# WUGEN_MPU register map
Vendor: Texas Instruments
Peripheral module from a debugger description file (folder omap5430_ES2_PUBLIC).
Registers are 32-bit, read-write, reset 0xFFFFFFFF unless marked. A register's access mark holds for its fields unless they carry their own. Offsets are as the file gives them; lines under a group give offsets from that group; [hi:lo] are bit positions; {n}, {i} and the like mark numbered series; 'fields as' and 'values as' point back to an identical list; <NAME> marks a mode.

## WUGEN_MPU
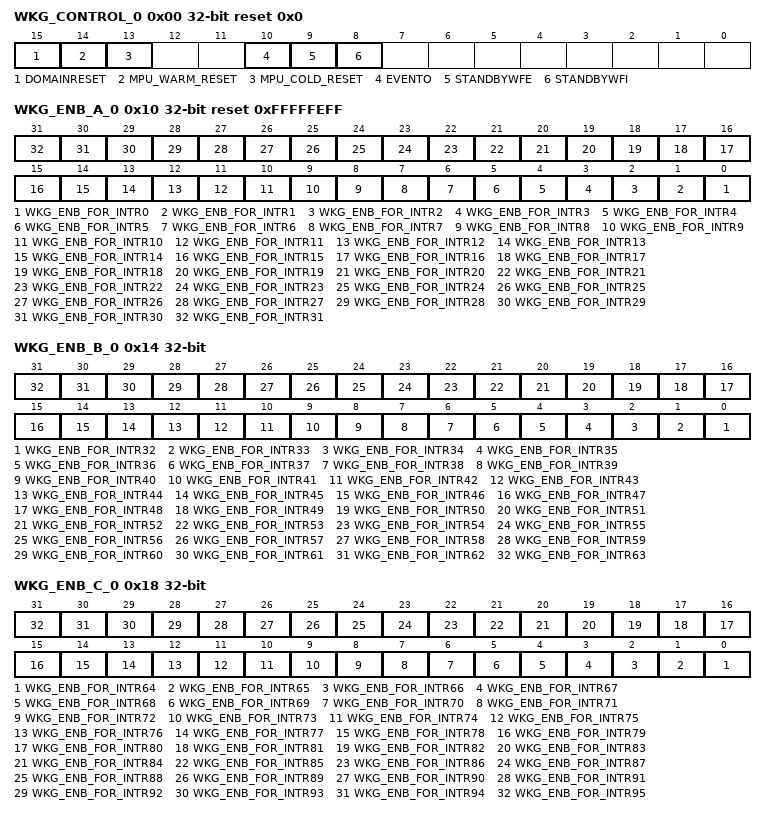
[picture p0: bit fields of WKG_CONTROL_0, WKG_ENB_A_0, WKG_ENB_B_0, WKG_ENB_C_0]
0x00 WKG_CONTROL_0 access not given reset 0x0 — Wake-up generator status register for MPU_C0
  [15] DOMAINRESET ro — MPU always-on power domain (PD_MPUAON) reset status bit. It shows if the reset occurred previously. 0x0: no reset occur 0x1: reset occur
  [14] MPU_WARM_RESET — This bit is set when the MPU_WARM_RESET signal is asserted. 0x0: MPU_WARM_RESET reset signal has not been asserted 0x1: MPU_WARM_RESET reset request has been asserted (access RW (WCtoClr))
  [13] MPU_COLD_RESET — This bit is set when the MPU_COLD_RESET signal is asserted. 0x0: MPU_COLD_RESET reset signal has not been asserted 0x1: MPU_COLD_RESET reset request has been asserted (access RW (WCtoClr))
  [10] EVENTO — EVENTO status bit. The event output signal is active, when one SEV instruction is executed. This bit is set when a rising edge of EVENTO from CPU is detected. 0x0: Rising edge of EVENTO is not detected 0x1: Rising edge of EVENTO is detected (access RW (WCtoClr))
  [9] STANDBYWFE — This bit gives software the visibility to track whether WFE mode have been entered. 0x0: WFE mode has not been entered 0x1: WFE mode has been entered (access RW (WCtoClr))
  [8] STANDBYWFI — This bit gives software the visibility to track whether WFI mode have been entered. 0x0: WFI mode has not been entered 0x1: WFI mode has been entered (access RW (WCtoClr))
0x10 WKG_ENB_A_0 reset 0xFFFFFEFF — This register enables the interrupts (for MPU_C0) from MPU_IRQ_0 to MPU_IRQ_31. Write 0x0:Disable interrupt. Write 0x1: Enable interrupt.
  [n] WKG_ENB_FOR_INTR{n} (n=0..31)
0x14 WKG_ENB_B_0 — This register enables the interrupts (for MPU_C0) from MPU_IRQ_32 to MPU_IRQ_63. Write 0x0: Disable interrupt. Write 0x1: Enable interrupt.
  [n-32] WKG_ENB_FOR_INTR{n} (n=32..63)
0x18 WKG_ENB_C_0 — This register enables the interrupts (for MPU_C0) from MPU_IRQ_64 to MPU_IRQ_95. Write 0x0: Disable interrupt. Write 0x1: Enable interrupt.
  [n-64] WKG_ENB_FOR_INTR{n} (n=64..95)
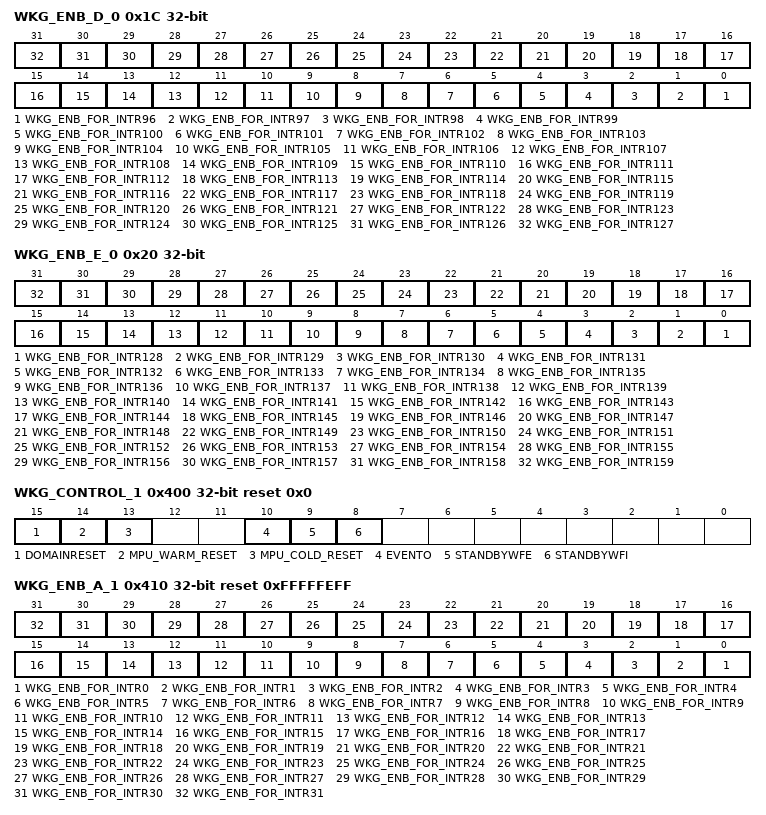
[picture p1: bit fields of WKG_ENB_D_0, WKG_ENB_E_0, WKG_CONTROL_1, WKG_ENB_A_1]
0x1C WKG_ENB_D_0 — This register enables the interrupts (for MPU_C0) from MPU_IRQ_96 to MPU_IRQ_127. Write 0x0: Disable interrupt. Write 0x1: Enable interrupt.
  [n-96] WKG_ENB_FOR_INTR{n} (n=96..127)
0x20 WKG_ENB_E_0 — This register enables the interrupts (for MPU_C0) from MPU_IRQ_128 to MPU_IRQ_159. Write 0x0: Disable interrupt. Write 0x1: Enable interrupt.
  [n-128] WKG_ENB_FOR_INTR{n} (n=128..159)
0x400 WKG_CONTROL_1 access not given reset 0x0 — Wake-up generator status register for MPU_C1
  [15] DOMAINRESET — MPU always-on power domain (PD_MPUAON) reset status bit. It shows if the reset occurred previously. 0x0: No reset occurred. 0x1: Reset occurred. (access RW (WCtoClr))
  [14] MPU_WARM_RESET — This bit is set when the MPU_WARM_RESET signal is asserted. 0x0: MPU_WARM_RESET reset signal has not been asserted. 0x1: MPU_WARM_RESET reset request has been asserted. (access RW (WCtoClr))
  [13] MPU_COLD_RESET — This bit is set when the MPU_COLD_RESET signal is asserted. 0x0: MPU_COLD_RESET reset signal has not been asserted. 0x1: MPU_COLD_RESET reset request has been asserted. (access RW (WCtoClr))
  [10] EVENTO — EVENTO status bit. The event output signal is active, when one SEV instruction is executed. This bit is set when a rising edge of EVENTO from CPU is detected. 0x0: Rising edge of EVENTO is not detected. 0x1: Rising edge of EVENTO is detected. (access RW (WCtoClr))
  [9] STANDBYWFE — This bit gives software the visibility to track whether WFE mode have been entered. 0x0: WFE mode has not been entered. 0x1: WFE mode has been entered. (access RW (WCtoClr))
  [8] STANDBYWFI — This bit gives software the visibility to track whether WFI mode have been entered. 0x0: WFI mode has not been entered. 0x1: WFI mode has been entered. (access RW (WCtoClr))
0x410 WKG_ENB_A_1 reset 0xFFFFFEFF — This register enables the interrupts (for MPU_C1) from MPU_IRQ_0 to MPU_IRQ_31. Write 0x0: Disable interrupt. Write 0x1: Enable interrupt.
  [n] WKG_ENB_FOR_INTR{n} (n=0..31)
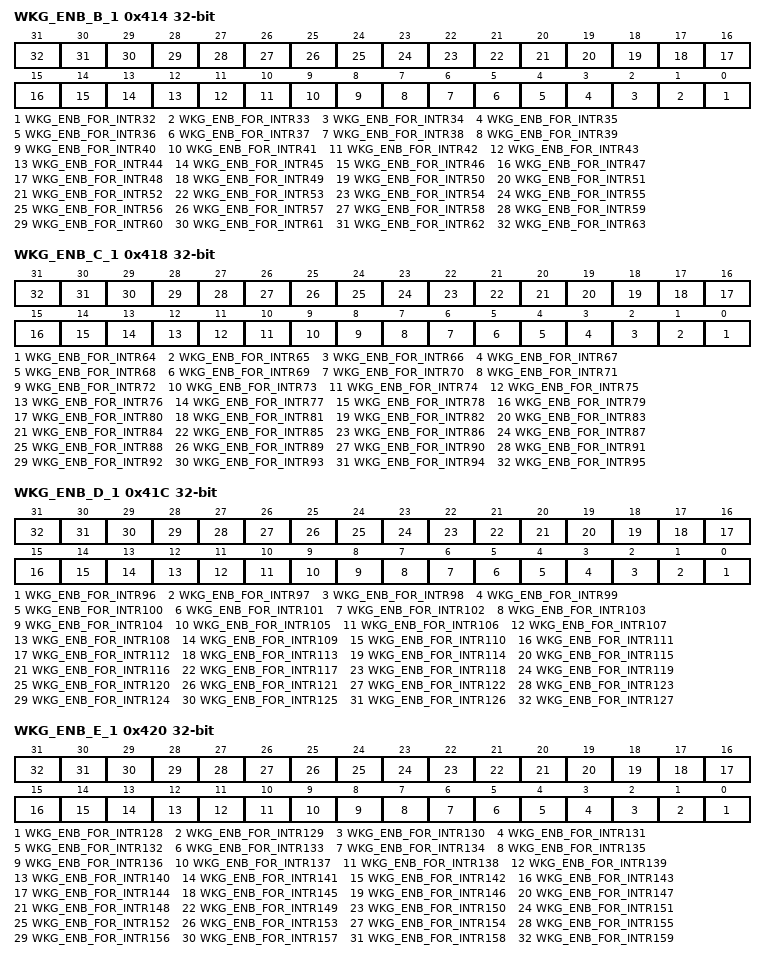
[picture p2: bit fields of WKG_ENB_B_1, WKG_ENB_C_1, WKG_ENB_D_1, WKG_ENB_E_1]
0x414 WKG_ENB_B_1 — This register enables the interrupts (for MPU_C1) from MPU_IRQ_32 to MPU_IRQ_63. Write 0x0: Disable interrupt. Write 0x1: Enable interrupt.
  [n-32] WKG_ENB_FOR_INTR{n} (n=32..63)
0x418 WKG_ENB_C_1 — This register enables the interrupts (for MPU_C1) from MPU_IRQ_64 to MPU_IRQ_95. Write 0x0: Disable interrupt. Write 0x1: Enable interrupt.
  [n-64] WKG_ENB_FOR_INTR{n} (n=64..95)
0x41C WKG_ENB_D_1 — This register enables the interrupts (for MPU_C1) from MPU_IRQ_96 to MPU_IRQ_127. Write 0x0: Disable interrupt. Write 0x1: Enable interrupt.
  [n-96] WKG_ENB_FOR_INTR{n} (n=96..127)
0x420 WKG_ENB_E_1 — This register enables the interrupts (for MPU_C1) from MPU_IRQ_128 to MPU_IRQ_159. Write 0x0: Disable interrupt. Write 0x1: Enable interrupt.
  [n-128] WKG_ENB_FOR_INTR{n} (n=128..159)
0x800 AUX_CORE_BOOT_0 reset 0x0 — This register is used by the ROM code and OS during SMP boot. It is intended to store the execution start address of MPU_C1. When needed, the SMP OS (executing on the MPU_C0) wakes up MPU_C1 by executing a SEV command. MPU_C0 needs to communicate some start-up information (for example, the starting address) to MPU_C1.
  [31:0] AUX_CORE_BOOT_0 — SMP boot register
0x804 AUX_CORE_BOOT_1 reset 0x0 — This register is used by the ROM code and OS during SMP boot. It is used to indicate boot status to either MPU core. When MPU_C1 receives an event (caused by the SEV command), it continues execution in the ROM, which set up the code to branch to the address signaled by MPU_C0.
  [31:0] AUX_CORE_BOOT_1 — SMP boot register
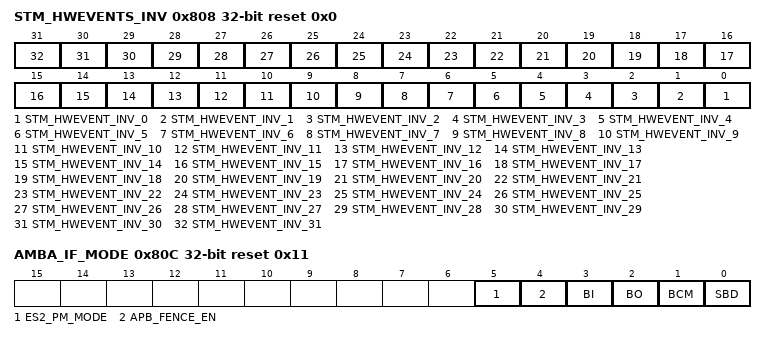
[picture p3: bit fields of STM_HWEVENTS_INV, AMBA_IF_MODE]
0x808 STM_HWEVENTS_INV reset 0x0 — Gives programmable control of inverting or not inverting MPUHWDBGOUT[31:0] going to HWEVENTS[31:0] input of CS_STM
  [n] STM_HWEVENT_INV_{n} (n=0..31) — Polarity inversion control for MPUHWDBGOUT{n} signal.
0x80C AMBA_IF_MODE access per field reset 0x11 — This register controls the MPU core interface tie-off values for BI, BO, BCM and SBD. This register is located in MPU always-on domain and is reset by MPUAON_RST.
  [5] ES2_PM_MODE rw — Enables ES2 PM Mode. 0x0: ES1 behavior, MPU cores would enter and exit OFF mode together. 0x1: ES2 behavior, MPU cores are allowed to enter/exit OFF mode independently.
  [4] APB_FENCE_EN rw — Enables APB fencing logic.
  [3] BI rw — BROADCASTINNER input of MPU core.
  [2] BO rw — BROADCASTOUTER input of MPU core.
  [1] BCM rw — BROADCASTMAINTENANCE input of MPU core.
  [0] SBD rw — SYSBARDISABLE input of MPU core.
0xC08 TIMESTAMPCYCLELO ro reset 0x0 — Lower 32 bits of the 48-bit timestamp counter value
  [31:0] COUNTER_31_0 — Lower 32 bits of the 48-bit timestamp counter value.
0xC0C TIMESTAMPCYCLEHI ro reset 0x0 — Higher 16 bits of the 48-bit timestamp counter value
  [15:0] COUNTER_47_32 — Higher 16 bits of the timestamp counter value.
